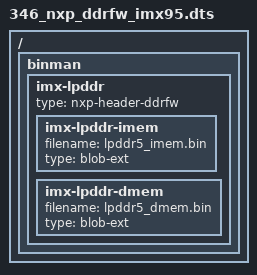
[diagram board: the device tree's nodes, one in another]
// SPDX-License-Identifier: GPL-2.0+

/dts-v1/;

/ {
	#address-cells = <1>;
	#size-cells = <1>;

	binman {
		imx-lpddr {
			type = "nxp-header-ddrfw";

			imx-lpddr-imem {
				filename = "lpddr5_imem.bin";
				type = "blob-ext";
			};

			imx-lpddr-dmem {
				filename = "lpddr5_dmem.bin";
				type = "blob-ext";
			};
		};
	};
};
